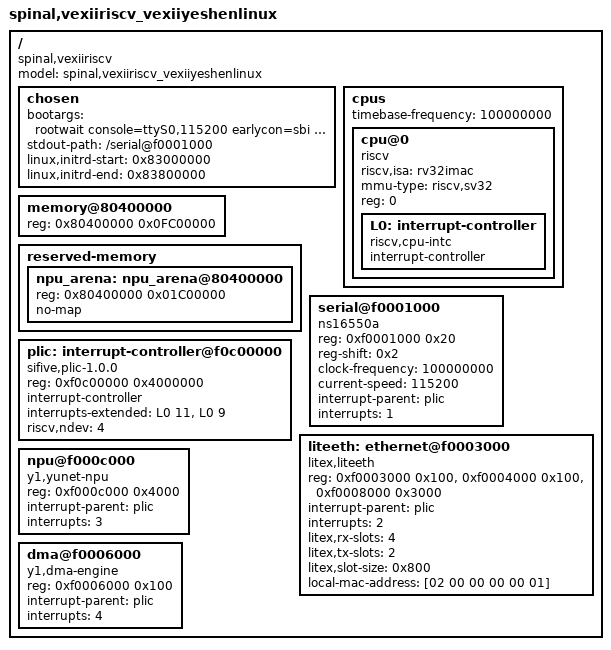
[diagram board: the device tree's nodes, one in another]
/dts-v1/;
#include <dt-bindings/gpio/gpio.h>
#include <dt-bindings/input/input.h>
#include <dt-bindings/interrupt-controller/irq.h>
/ {
    #address-cells = <0x1>;
    #size-cells = <0x1>;
    compatible = "spinal,vexiiriscv";
    model = "spinal,vexiiriscv_vexiiyeshenlinux";
    chosen {
        bootargs = "rootwait console=ttyS0,115200 earlycon=sbi root=/dev/ram0 init=/init";
        stdout-path = "/serial@f0001000";
        linux,initrd-start = <0x83000000>;
        linux,initrd-end = <0x83800000>;
    };
    cpus {
        #address-cells = <0x1>;
        #size-cells = <0x0>;
        timebase-frequency = <100000000>;
        cpu@0 {
            device_type = "cpu";
            compatible = "riscv";
            riscv,isa = "rv32imac";
            mmu-type = "riscv,sv32";
            reg = <0>;
            status = "okay";
            L0: interrupt-controller {
                #interrupt-cells = <0x00000001>;
                interrupt-controller;
                compatible = "riscv,cpu-intc";
            };
        };
    };
    memory@80400000 {
        device_type = "memory";
        reg = <0x80400000 0x0FC00000>;
    };
    reserved-memory {
        #address-cells = <0x1>;
        #size-cells = <0x1>;
        ranges;
        npu_arena: npu_arena@80400000 {
            reg = <0x80400000 0x01C00000>;
            no-map;
        };
    };
    serial@f0001000 {
        compatible = "ns16550a";
        reg = <0xf0001000 0x20>;
        reg-shift = <0x2>;
        clock-frequency = <100000000>;
        current-speed = <115200>;
        interrupt-parent = <&plic>;
        interrupts = <1>;
        status = "okay";
    };
    plic: interrupt-controller@f0c00000 {
        compatible = "sifive,plic-1.0.0", "sifive,fu540-c000-plic", "riscv,plic0";
        reg = <0xf0c00000 0x4000000>;
        interrupt-controller;
        #address-cells = <0x0>;
        #interrupt-cells = <0x1>;
        interrupts-extended = <&L0 11 &L0 9>;
        riscv,ndev = <4>;
    };
    liteeth: ethernet@f0003000 {
        compatible = "litex,liteeth";
        reg = <0xf0003000 0x100>,
              <0xf0004000 0x100>,
              <0xf0008000 0x3000>;
        reg-names = "mac", "mdio", "buffer";
        interrupt-parent = <&plic>;
        interrupts = <2>;
        litex,rx-slots = <4>;
        litex,tx-slots = <2>;
        litex,slot-size = <0x800>;
        local-mac-address = [02 00 00 00 00 01];
        status = "okay";
    };
    npu@f000c000 {
        compatible = "y1,yunet-npu";
        reg = <0xf000c000 0x4000>;
        interrupt-parent = <&plic>;
        interrupts = <3>;
        status = "okay";
    };
    dma@f0006000 {
        compatible = "y1,dma-engine";
        reg = <0xf0006000 0x100>;
        interrupt-parent = <&plic>;
        interrupts = <4>;
        status = "okay";
    };
};
